# DSS_EDP0_K3_DSS_EDP_MHDPTX_WRAPPER_ECC_AGGR_PHY_MHDPTX_WRAPPER_ECC_AGGR_PHY_CFG register map
Vendor: Texas Instruments
Peripheral module from a debugger description file (folder J7_AHP).
Registers are 32-bit, access not given, reset 0x0 unless marked. A register's access mark holds for its fields unless they carry their own. Offsets are as the file gives them; lines under a group give offsets from that group; [hi:lo] are bit positions; {n}, {i} and the like mark numbered series; 'fields as' and 'values as' point back to an identical list; <NAME> marks a mode.

## DSS_EDP0_K3_DSS_EDP_MHDPTX_WRAPPER_ECC_AGGR_PHY_MHDPTX_WRAPPER_ECC_AGGR_PHY_CFG
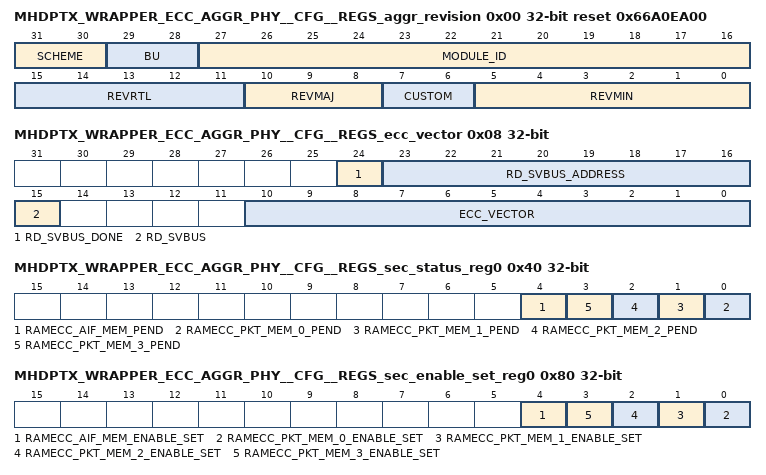
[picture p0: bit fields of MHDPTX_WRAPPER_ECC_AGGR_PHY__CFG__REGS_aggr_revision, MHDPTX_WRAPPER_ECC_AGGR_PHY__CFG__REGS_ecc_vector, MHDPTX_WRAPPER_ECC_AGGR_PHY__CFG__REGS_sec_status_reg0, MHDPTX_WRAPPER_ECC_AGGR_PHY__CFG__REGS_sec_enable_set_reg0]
0x00 MHDPTX_WRAPPER_ECC_AGGR_PHY__CFG__REGS_aggr_revision ro reset 0x66A0EA00
  [31:30] SCHEME
  [29:28] BU
  [27:16] MODULE_ID
  [15:11] REVRTL — RTL version
  [10:8] REVMAJ — Major version
  [7:6] CUSTOM — Custom version
  [5:0] REVMIN — Minor version
0x08 MHDPTX_WRAPPER_ECC_AGGR_PHY__CFG__REGS_ecc_vector
  [24] RD_SVBUS_DONE — Status to indicate if read on serial VBUS is complete, write of any value will clear this bit. (access R/W1TC)
  [23:16] RD_SVBUS_ADDRESS rw — Read address
  [15] RD_SVBUS — Write 1 to trigger a read on the serial VBUS (access R/W1TS)
  [10:0] ECC_VECTOR rw — Value written to select the corresponding ECC RAM for control or status
0x0C MHDPTX_WRAPPER_ECC_AGGR_PHY__CFG__REGS_misc_status ro reset 0x5
  [10:0] NUM_RAMS — Indicates the number of RAMS serviced by the ECC aggregator
0x10 MHDPTX_WRAPPER_ECC_AGGR_PHY__CFG__REGS_reserved_svbus rw
  [31:0] DATA — Serial VBUS register data
0x3C MHDPTX_WRAPPER_ECC_AGGR_PHY__CFG__REGS_sec_eoi_reg
  [0] EOI_WR — EOI Register (access R/W1TS)
0x40 MHDPTX_WRAPPER_ECC_AGGR_PHY__CFG__REGS_sec_status_reg0
  [4] RAMECC_AIF_MEM_PEND — Interrupt Pending Status for ramecc_aif_mem_pend (access R/W1TS)
  [n] RAMECC_PKT_MEM_{n}_PEND (n=0..3) — Interrupt Pending Status for ramecc_pkt_mem_{n}_pend (access R/W1TS)
0x80 MHDPTX_WRAPPER_ECC_AGGR_PHY__CFG__REGS_sec_enable_set_reg0
  [4] RAMECC_AIF_MEM_ENABLE_SET — Interrupt Enable Set Register for ramecc_aif_mem_pend (access R/W1TS)
  [n] RAMECC_PKT_MEM_{n}_ENABLE_SET (n=0..3) — Interrupt Enable Set Register for ramecc_pkt_mem_{n}_pend (access R/W1TS)
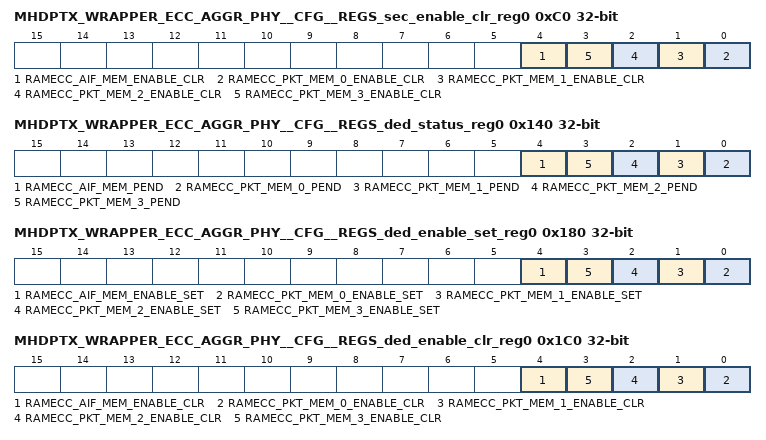
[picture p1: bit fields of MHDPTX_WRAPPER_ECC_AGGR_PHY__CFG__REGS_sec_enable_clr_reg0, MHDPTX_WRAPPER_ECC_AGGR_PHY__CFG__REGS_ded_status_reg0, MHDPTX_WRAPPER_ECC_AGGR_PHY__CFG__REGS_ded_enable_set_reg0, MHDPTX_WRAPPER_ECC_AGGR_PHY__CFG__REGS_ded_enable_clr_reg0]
0xC0 MHDPTX_WRAPPER_ECC_AGGR_PHY__CFG__REGS_sec_enable_clr_reg0
  [4] RAMECC_AIF_MEM_ENABLE_CLR — Interrupt Enable Clear Register for ramecc_aif_mem_pend (access R/W1TC)
  [n] RAMECC_PKT_MEM_{n}_ENABLE_CLR (n=0..3) — Interrupt Enable Clear Register for ramecc_pkt_mem_{n}_pend (access R/W1TC)
0x13C MHDPTX_WRAPPER_ECC_AGGR_PHY__CFG__REGS_ded_eoi_reg
  [0] EOI_WR — EOI Register (access R/W1TS)
0x140 MHDPTX_WRAPPER_ECC_AGGR_PHY__CFG__REGS_ded_status_reg0
  fields as MHDPTX_WRAPPER_ECC_AGGR_PHY__CFG__REGS_sec_status_reg0
0x180 MHDPTX_WRAPPER_ECC_AGGR_PHY__CFG__REGS_ded_enable_set_reg0
  fields as MHDPTX_WRAPPER_ECC_AGGR_PHY__CFG__REGS_sec_enable_set_reg0
0x1C0 MHDPTX_WRAPPER_ECC_AGGR_PHY__CFG__REGS_ded_enable_clr_reg0
  fields as MHDPTX_WRAPPER_ECC_AGGR_PHY__CFG__REGS_sec_enable_clr_reg0
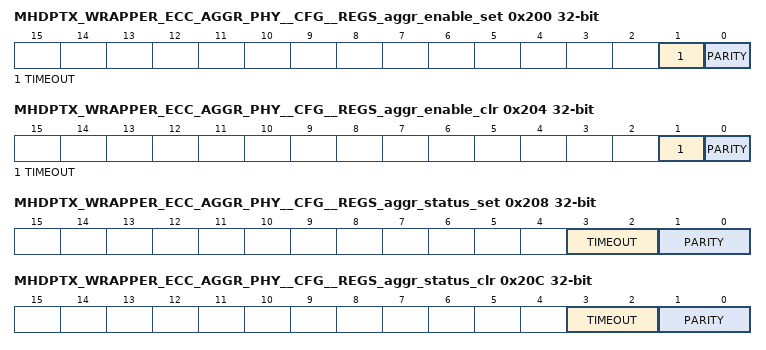
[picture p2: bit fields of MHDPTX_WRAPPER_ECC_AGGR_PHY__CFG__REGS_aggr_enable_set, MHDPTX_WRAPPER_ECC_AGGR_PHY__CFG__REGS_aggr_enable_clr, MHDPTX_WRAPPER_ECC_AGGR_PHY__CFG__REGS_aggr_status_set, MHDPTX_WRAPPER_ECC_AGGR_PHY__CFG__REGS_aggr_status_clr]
0x200 MHDPTX_WRAPPER_ECC_AGGR_PHY__CFG__REGS_aggr_enable_set
  [1] TIMEOUT — interrupt enable set for svbus timeout errors (access R/W1TS)
  [0] PARITY — interrupt enable set for parity errors (access R/W1TS)
0x204 MHDPTX_WRAPPER_ECC_AGGR_PHY__CFG__REGS_aggr_enable_clr
  [1] TIMEOUT — interrupt enable clear for svbus timeout errors (access R/W1TC)
  [0] PARITY — interrupt enable clear for parity errors (access R/W1TC)
0x208 MHDPTX_WRAPPER_ECC_AGGR_PHY__CFG__REGS_aggr_status_set
  [3:2] TIMEOUT — interrupt status set for svbus timeout errors (access R/WI)
  [1:0] PARITY — interrupt status set for parity errors (access R/WI)
0x20C MHDPTX_WRAPPER_ECC_AGGR_PHY__CFG__REGS_aggr_status_clr
  [3:2] TIMEOUT — interrupt status clear for svbus timeout errors (access R/WD)
  [1:0] PARITY — interrupt status clear for parity errors (access R/WD)
